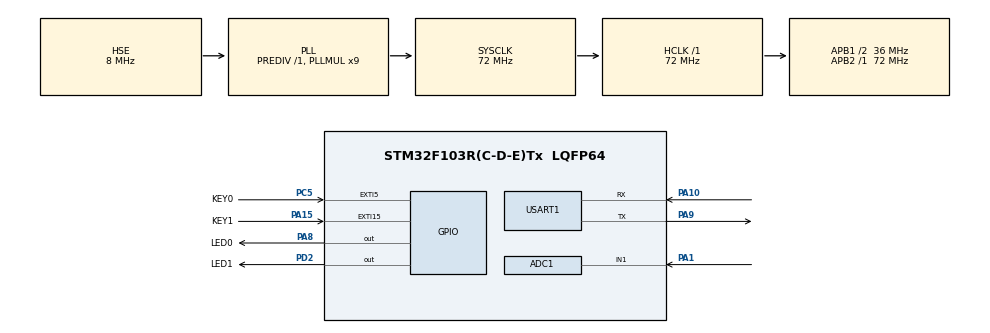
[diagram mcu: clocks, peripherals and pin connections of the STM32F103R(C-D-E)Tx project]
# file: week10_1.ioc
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ADC1.Channel-0\#ChannelRegularConversion=ADC_CHANNEL_1
ADC1.NbrOfConversionFlag=1
ADC1.Rank-0\#ChannelRegularConversion=1
ADC1.SamplingTime-0\#ChannelRegularConversion=ADC_SAMPLETIME_1CYCLE_5
ADC1.master=1
IWDG.Prescaler=IWDG_PRESCALER_64
IWDG.Reload=1250
Mcu.Family=STM32F1
Mcu.Name=STM32F103R(C-D-E)Tx
Mcu.Package=LQFP64
NVIC.EXTI15_10_IRQn=true\:1\:0\:true\:false\:true\:true\:true
NVIC.EXTI9_5_IRQn=true\:1\:0\:true\:false\:true\:true\:true
NVIC.PriorityGroup=NVIC_PRIORITYGROUP_4
NVIC.WWDG_IRQn=true\:0\:0\:false\:false\:true\:true\:true
PA1.Signal=ADCx_IN1
PA10.Mode=Asynchronous
PA10.Signal=USART1_RX
PA13.Mode=Serial_Wire
PA13.Signal=SYS_JTMS-SWDIO
PA14.Mode=Serial_Wire
PA14.Signal=SYS_JTCK-SWCLK
PA15.GPIO_Label=KEY1
PA15.GPIO_PuPd=GPIO_PULLUP
PA15.Signal=GPXTI15
PA8.GPIO_Label=LED0
PA8.Signal=GPIO_Output
PA9.Mode=Asynchronous
PA9.Signal=USART1_TX
PC5.GPIO_Label=KEY0
PC5.GPIO_PuPd=GPIO_PULLUP
PC5.Signal=GPXTI5
PD0-OSC_IN.Mode=HSE-External-Oscillator
PD0-OSC_IN.Signal=RCC_OSC_IN
PD1-OSC_OUT.Mode=HSE-External-Oscillator
PD1-OSC_OUT.Signal=RCC_OSC_OUT
PD2.GPIO_Label=LED1
PD2.GPIO_ModeDefaultOutputPP=GPIO_MODE_OUTPUT_PP
PD2.Signal=GPIO_Output
ProjectManager.HeapSize=0x200
ProjectManager.StackSize=0x400
ProjectManager.TargetToolchain=STM32CubeIDE
RCC.ADCPresc=RCC_ADCPCLK2_DIV6
RCC.AHBFreq_Value=72000000
RCC.APB1CLKDivider=RCC_HCLK_DIV2
RCC.APB1Freq_Value=36000000
RCC.APB1TimFreq_Value=72000000
RCC.APB2Freq_Value=72000000
RCC.APB2TimFreq_Value=72000000
RCC.HCLKFreq_Value=72000000
RCC.PLLMUL=RCC_PLL_MUL9
RCC.PLLSourceVirtual=RCC_PLLSOURCE_HSE
RCC.SYSCLKFreq_VALUE=72000000
RCC.SYSCLKSource=RCC_SYSCLKSOURCE_PLLCLK
RCC.USBFreq_Value=72000000
SH.ADCx_IN1.0=ADC1_IN1,IN1
USART1.VirtualMode=VM_ASYNC
VP_IWDG_VS_IWDG.Mode=IWDG_Activate
VP_WWDG_VS_WWDG.Mode=WWDG_Activate
WWDG.Counter=127
WWDG.EWIMode=WWDG_EWI_ENABLE
WWDG.Window=95
board=custom

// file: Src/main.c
/* USER CODE BEGIN Header */
/**
 ******************************************************************************
 * @file           : main.c
 * @brief          : Main program body
 ******************************************************************************
 * @attention
 *
 * <h2><center>&copy; Copyright (c) 2019 STMicroelectronics.
 * All rights reserved.</center></h2>
 *
 * This software component is licensed by ST under BSD 3-Clause license,
 * the "License"; You may not use this file except in compliance with the
 * License. You may obtain a copy of the License at:
 *                        opensource.org/licenses/BSD-3-Clause
 *
 ******************************************************************************
 */
/* USER CODE END Header */

#include "main.h"
#include "adc.h"
#include "iwdg.h"
#include "usart.h"
#include "wwdg.h"
#include "gpio.h"

void SystemClock_Config(void);

int main(void) {

	/* MCU Configuration--------------------------------------------------------*/

	/* Reset of all peripherals, Initializes the Flash interface and the Systick. */
	HAL_Init();

	/* Configure the system clock */
	SystemClock_Config();

	/* Initialize all configured peripherals */
	MX_GPIO_Init();
	MX_ADC1_Init();
	MX_IWDG_Init();
	MX_USART1_UART_Init();
	MX_WWDG_Init();

	/* Infinite loop */
	/* USER CODE BEGIN WHILE */
	int i = 0;
	int count = 0;
	uint16_t raw;
	/*REset 按住 set 松开
	 * KEY_1 right 2nd
	 * Key_0 left 2nd
	 * */
	unsigned char msg[20] = { 0 };
	unsigned char unpress[20] = { 0x4B, 0x45, 0x59, 0x31, 0x20, 0x44, 0x4F,
			0x4E, 0x54, 0x20, 0x50, 0x52, 0x45, 0x53, 0x53, 0x0D, 0x0A };
	while (1) {
		if (HAL_GPIO_ReadPin(KEY1_GPIO_Port, KEY1_Pin) == GPIO_PIN_SET) {
			HAL_UART_Transmit(&huart1, (uint8_t*) unpress, strlen(unpress),
					HAL_MAX_DELAY);
		}
		/* USER CODE END WHILE */
		HAL_Delay(300);
		HAL_GPIO_TogglePin(LED0_GPIO_Port, LED0_Pin);
		HAL_GPIO_TogglePin(LED1_GPIO_Port, LED1_Pin);
		HAL_IWDG_Refresh(&hiwdg);
	    i++;
		sprintf(msg, "%d\r\n", i);
		HAL_UART_Transmit(&huart1, (uint8_t*) msg, strlen(msg), HAL_MAX_DELAY);
		HAL_ADC_Start(&hadc1);
		HAL_ADC_PollForConversion(&hadc1, HAL_MAX_DELAY);
		raw = HAL_ADC_GetValue(&hadc1);
		float middle = raw * (3.3 / 4096);
		float Temprator = (1.43 - middle) / 4.3 + 25;
		sprintf(msg, "%.6f\r\n", Temprator);
		HAL_UART_Transmit(&huart1, (uint8_t *) msg, strlen(msg), HAL_MAX_DELAY);
	}
}

void SystemClock_Config(void) {
	RCC_OscInitTypeDef RCC_OscInitStruct = { 0 };
	RCC_ClkInitTypeDef RCC_ClkInitStruct = { 0 };
	RCC_PeriphCLKInitTypeDef PeriphClkInit = { 0 };

	/** Initializes the CPU, AHB and APB busses clocks
	 */
	RCC_OscInitStruct.OscillatorType = RCC_OSCILLATORTYPE_LSI
			| RCC_OSCILLATORTYPE_HSE;
	RCC_OscInitStruct.HSEState = RCC_HSE_ON;
	RCC_OscInitStruct.HSEPredivValue = RCC_HSE_PREDIV_DIV1;
	RCC_OscInitStruct.HSIState = RCC_HSI_ON;
	RCC_OscInitStruct.LSIState = RCC_LSI_ON;
	RCC_OscInitStruct.PLL.PLLState = RCC_PLL_ON;
	RCC_OscInitStruct.PLL.PLLSource = RCC_PLLSOURCE_HSE;
	RCC_OscInitStruct.PLL.PLLMUL = RCC_PLL_MUL9;
	if (HAL_RCC_OscConfig(&RCC_OscInitStruct) != HAL_OK) {
		Error_Handler();
	}
	/** Initializes the CPU, AHB and APB busses clocks
	 */
	RCC_ClkInitStruct.ClockType = RCC_CLOCKTYPE_HCLK | RCC_CLOCKTYPE_SYSCLK
			| RCC_CLOCKTYPE_PCLK1 | RCC_CLOCKTYPE_PCLK2;
	RCC_ClkInitStruct.SYSCLKSource = RCC_SYSCLKSOURCE_PLLCLK;
	RCC_ClkInitStruct.AHBCLKDivider = RCC_SYSCLK_DIV1;
	RCC_ClkInitStruct.APB1CLKDivider = RCC_HCLK_DIV2;
	RCC_ClkInitStruct.APB2CLKDivider = RCC_HCLK_DIV1;

	if (HAL_RCC_ClockConfig(&RCC_ClkInitStruct, FLASH_LATENCY_2) != HAL_OK) {
		Error_Handler();
	}
	PeriphClkInit.PeriphClockSelection = RCC_PERIPHCLK_ADC;
	PeriphClkInit.AdcClockSelection = RCC_ADCPCLK2_DIV6;
	if (HAL_RCCEx_PeriphCLKConfig(&PeriphClkInit) != HAL_OK) {
		Error_Handler();
	}
}

void Error_Handler(void) {
}

/************************ (C) COPYRIGHT STMicroelectronics *****END OF FILE****/
